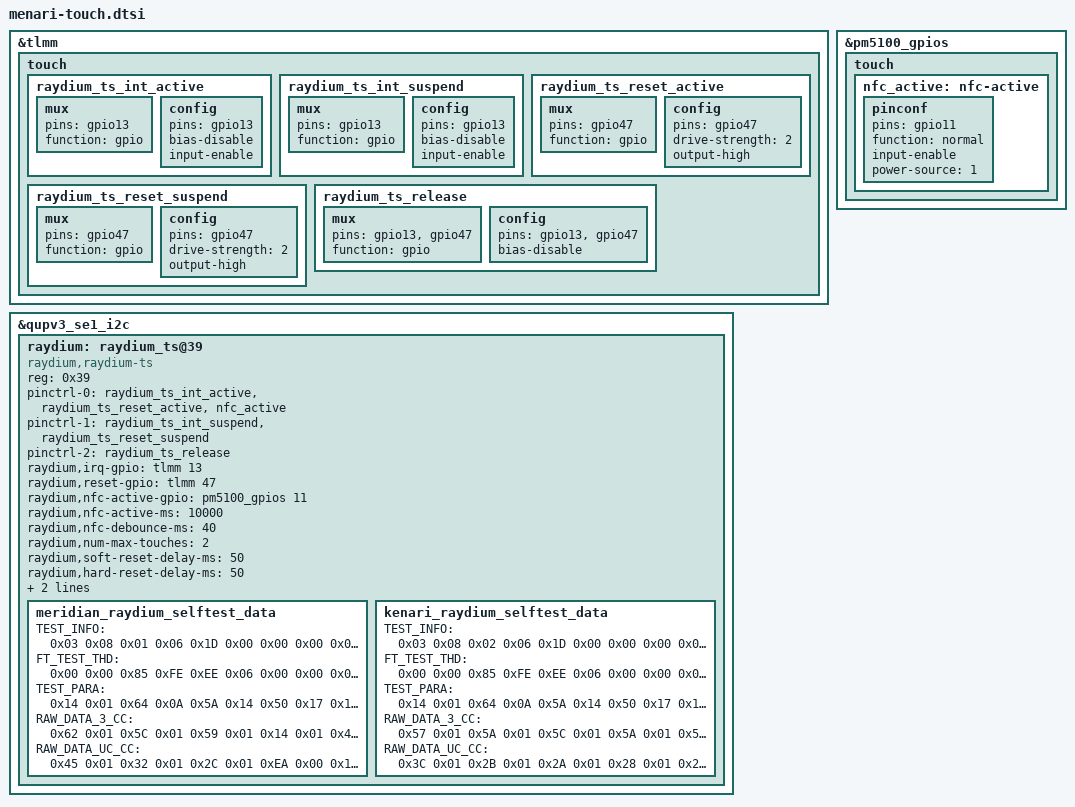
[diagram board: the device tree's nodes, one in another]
// SPDX-License-Identifier: GPL-2.0

#include <dt-bindings/gpio/gpio.h>

&tlmm {
	touch {
		raydium_ts_int_active: raydium_ts_int_active {
			mux {
				pins = "gpio13";
				function = "gpio";
			};

			config {
				pins = "gpio13";
				bias-disable;
				input-enable;
			};
		};

		raydium_ts_int_suspend: raydium_ts_int_suspend {
			mux {
				pins = "gpio13";
				function = "gpio";
			};

			config {
				pins = "gpio13";
				bias-disable;
				input-enable;
			};
		};

		raydium_ts_reset_active: raydium_ts_reset_active {
			mux {
				pins = "gpio47";
				function = "gpio";
			};

			config {
				pins = "gpio47";
				drive-strength = <2>;
				output-high;
			};
		};


		raydium_ts_reset_suspend: raydium_ts_reset_suspend {
			mux {
				pins = "gpio47";
				function = "gpio";
			};

			config {
				pins = "gpio47";
				drive-strength = <2>;
				output-high;
			};
		};

		raydium_ts_release: raydium_ts_release {
			mux {
				pins = "gpio13", "gpio47";
				function = "gpio";
			};

			config {
				pins = "gpio13", "gpio47";
				bias-disable;
			};
		};
	};
};

&pm5100_gpios {
	touch {
		nfc_active: nfc-active {
			pinconf {
				pins = "gpio11";
				function = "normal";
				input-enable;
				power-source = <1>;
			};
		};
	};
};

&qupv3_se1_i2c {
	#address-cells = <1>;
	#size-cells = <0>;

	status = "okay";

	raydium: raydium_ts@39 {
		compatible = "raydium,raydium-ts";
		reg = <0x39>;
		status = "okay";

		pinctrl-names = "pmx_ts_active","pmx_ts_suspend","pmx_ts_release";
		pinctrl-0 = <&raydium_ts_int_active &raydium_ts_reset_active &nfc_active>;
		pinctrl-1 = <&raydium_ts_int_suspend &raydium_ts_reset_suspend>;
		pinctrl-2 = <&raydium_ts_release>;

		raydium,irq-gpio = <&tlmm 13 0x00>;
		raydium,reset-gpio = <&tlmm 47 0x00>;

		raydium,nfc-active-gpio = <&pm5100_gpios 11 GPIO_ACTIVE_HIGH>;
		raydium,nfc-active-ms = <10000>;
		raydium,nfc-debounce-ms = <40>;

		raydium,num-max-touches = <2>;
		raydium,soft-reset-delay-ms = <50>;
		raydium,hard-reset-delay-ms = <50>;

		raydium,esd-protect-enable;

		touch,identifier = "Raydium RM6D031";
	};
};

&raydium {
	meridian_raydium_selftest_data: meridian_raydium_selftest_data {
		TEST_INFO = /bits/ 8 <
			0x03 0x08 0x01 0x06 0x1D 0x00 0x00 0x00
			0x00 0x00 0x00 0x00 0x00 0x00 0x00 0x00>;
		FT_TEST_THD = /bits/ 8 <
			0x00 0x00 0x85 0xFE 0xEE 0x06 0x00 0x00 0x00 0x00 0xFC 0xFE
			0x00 0x00 0x00 0x00 0x5B 0x00 0xA5 0xFF 0x3F 0x00 0x2E 0x00
			0x3F 0x00 0x3F 0x00 0x07 0x00 0x00 0x00 0x00 0x00 0x00 0x00>;
		TEST_PARA = /bits/ 8 <
			0x14 0x01 0x64 0x0A 0x5A 0x14 0x50 0x17 0x12 0x00 0x03 0x1E
			0x0F 0x01 0x64 0x17 0x12 0x02 0x00 0x00 0x10 0xA3 0x12 0x02
			0x08 0x00 0x04 0x23 0x44 0x00 0x00 0x00 0x40 0x08 0x02 0x00
			0x00 0x00 0x00 0x00 0x08 0x01 0x03 0x00 0x08 0x01 0x40 0x00>;
		RAW_DATA_3_CC = /bits/ 8 <
			0x62 0x01 0x5C 0x01 0x59 0x01 0x14 0x01 0x47 0x01 0x48 0x01
			0x4A 0x01 0xBE 0x00 0x3A 0x01 0x3C 0x01 0xF1 0x00 0xE6 0x00
			0x21 0x01 0x1E 0x01 0xA0 0x00 0x20 0x01 0x1E 0x01 0x1C 0x01
			0xE7 0x00 0x16 0x01 0x00 0x00 0x00 0x00 0x1C 0x01 0x20 0x01
			0x60 0x01 0x5B 0x01 0x58 0x01 0x11 0x01 0x46 0x01 0x49 0x01
			0x4B 0x01 0xBA 0x00 0x39 0x01 0x3C 0x01 0xEA 0x00 0xDF 0x00
			0x22 0x01 0x1E 0x01 0x9D 0x00 0x22 0x01 0x1E 0x01 0x1D 0x01
			0xE6 0x00 0x19 0x01 0x1E 0x01 0x22 0x01 0x00 0x00 0x00 0x00>;
		RAW_DATA_UC_CC = /bits/ 8 <
			0x45 0x01 0x32 0x01 0x2C 0x01 0xEA 0x00 0x1F 0x01 0x20 0x01
			0x22 0x01 0x9D 0x00 0x18 0x01 0x1A 0x01 0xD6 0x00 0xD2 0x00
			0x0D 0x01 0x0A 0x01 0x90 0x00 0x0E 0x01 0x0B 0x01 0x0A 0x01
			0xD7 0x00 0x08 0x01 0x00 0x00 0x00 0x00 0x0F 0x01 0x14 0x01
			0x44 0x01 0x30 0x01 0x2A 0x01 0xE7 0x00 0x1E 0x01 0x20 0x01
			0x22 0x01 0x98 0x00 0x16 0x01 0x19 0x01 0xCF 0x00 0xCB 0x00
			0x0D 0x01 0x0A 0x01 0x91 0x00 0x0E 0x01 0x0B 0x01 0x0A 0x01
			0xD4 0x00 0x09 0x01 0x0D 0x01 0x13 0x01 0x00 0x00 0x00 0x00>;
	};
	kenari_raydium_selftest_data: kenari_raydium_selftest_data {
		TEST_INFO = /bits/ 8 <
			0x03 0x08 0x02 0x06 0x1D 0x00 0x00 0x00
			0x00 0x00 0x00 0x00 0x00 0x00 0x00 0x00>;
		FT_TEST_THD = /bits/ 8 <
			0x00 0x00 0x85 0xFE 0xEE 0x06 0x00 0x00 0x00 0x00 0xFC 0xFE
			0x00 0x00 0x00 0x00 0x53 0x00 0xAD 0xFF 0x3F 0x00 0x2E 0x00
			0x3F 0x00 0x3F 0x00 0x07 0x00 0x00 0x00 0x00 0x00 0x00 0x00>;
		TEST_PARA = /bits/ 8 <
			0x14 0x01 0x64 0x0A 0x5A 0x14 0x50 0x17 0x12 0x00 0x03 0x1E
			0x0F 0x01 0x64 0x17 0x12 0x02 0x00 0x00 0x10 0xA3 0x12 0x02
			0x08 0x00 0x04 0x23 0x44 0x00 0x00 0x00 0x40 0x08 0x02 0x00
			0x00 0x00 0x00 0x00 0x08 0x02 0x00 0x00 0x08 0x02 0x40 0x00>;
		RAW_DATA_3_CC = /bits/ 8 <
			0x57 0x01 0x5A 0x01 0x5C 0x01 0x5A 0x01 0x55 0x01 0x52 0x01
			0x3A 0x01 0x32 0x01 0x41 0x01 0x42 0x01 0x24 0x01 0x3F 0x02
			0x08 0x01 0x1C 0x01 0x19 0x01 0x0E 0x01 0x05 0x01 0x12 0x01
			0x14 0x01 0x18 0x01 0x1A 0x01 0x16 0x01 0x14 0x01 0x2C 0x02
			0x6C 0x02 0x56 0x01 0x58 0x01 0x5A 0x01 0x55 0x01 0x53 0x01
			0x4F 0x01 0x36 0x01 0x31 0x01 0x3D 0x01 0x3D 0x01 0x1E 0x01
			0x34 0x02 0x04 0x01 0x1E 0x01 0x1C 0x01 0x0E 0x01 0x04 0x01
			0x12 0x01 0x17 0x01 0x1C 0x01 0x1C 0x01 0x19 0x01 0x14 0x01>;
		RAW_DATA_UC_CC = /bits/ 8 <
			0x3C 0x01 0x2B 0x01 0x2A 0x01 0x28 0x01 0x23 0x01 0x20 0x01
			0x0D 0x01 0x0A 0x01 0x18 0x01 0x1A 0x01 0x02 0x01 0x20 0x02
			0xF2 0x00 0x09 0x01 0x04 0x01 0xF9 0x00 0xF2 0x00 0x00 0x01
			0x03 0x01 0x07 0x01 0x07 0x01 0x04 0x01 0x04 0x01 0x1E 0x02
			0x4D 0x02 0x2A 0x01 0x26 0x01 0x28 0x01 0x24 0x01 0x21 0x01
			0x1E 0x01 0x08 0x01 0x08 0x01 0x15 0x01 0x18 0x01 0xFC 0x00
			0x15 0x02 0xEF 0x00 0x0A 0x01 0x05 0x01 0xF8 0x00 0xF0 0x00
			0x00 0x01 0x04 0x01 0x09 0x01 0x08 0x01 0x06 0x01 0x08 0x01>;
	};
};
